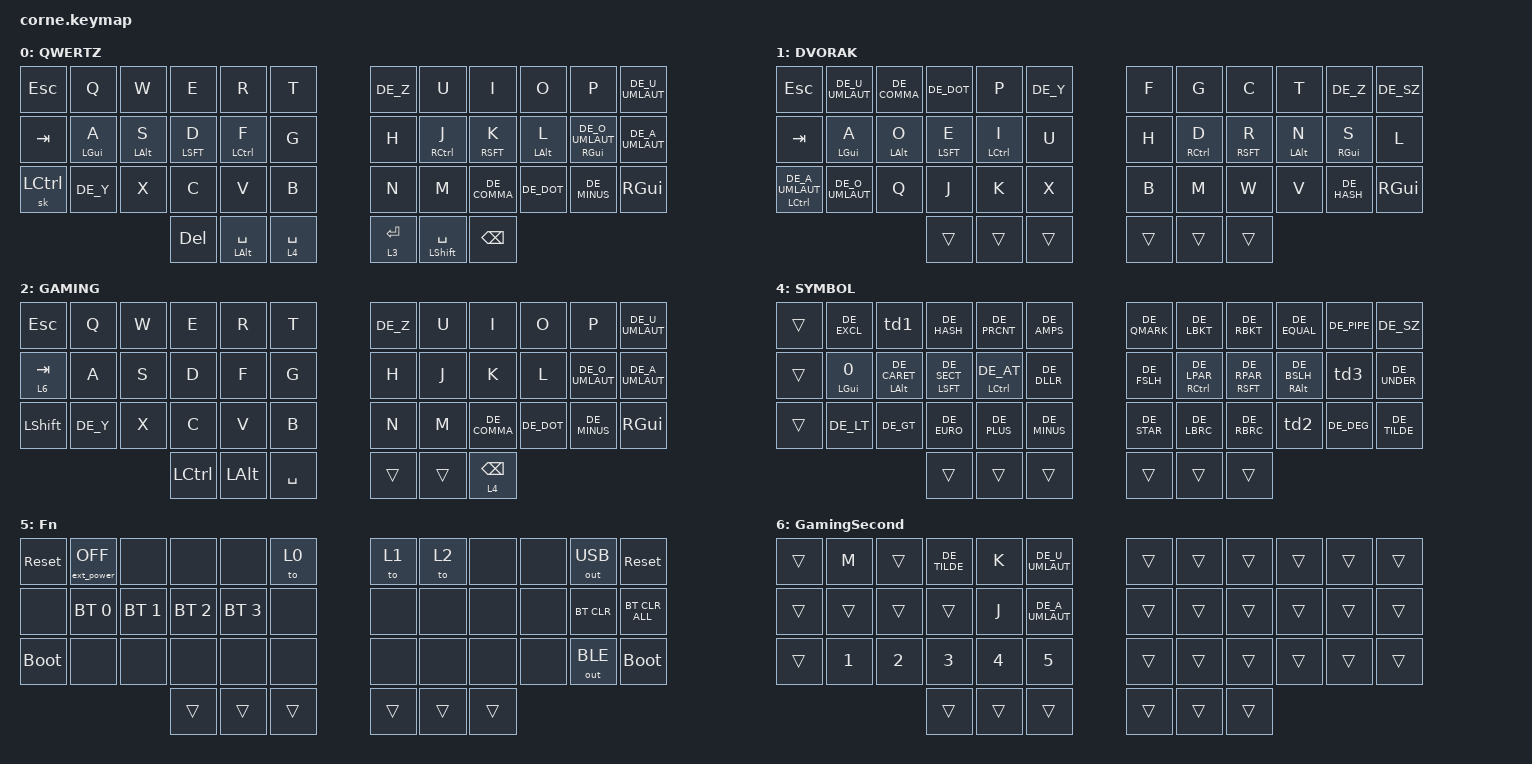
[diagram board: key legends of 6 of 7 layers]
/*
* Copyright (c) 2020 The ZMK Contributors
*
* SPDX-License-Identifier: MIT
*/

#include <behaviors.dtsi>
#include <dt-bindings/zmk/bt.h>
#include <dt-bindings/zmk/keys.h>
#include <dt-bindings/zmk/outputs.h>
#include <dt-bindings/zmk/rgb.h>
#include <dt-bindings/zmk/ext_power.h>
#include "keys_de.h"


/ {
  chosen {
    zmk,matrix_transform = &default_transform;

    // zmk,matrix_transform = &five_column_transform;
  };
};
  &soft_off { 
    hold-time-ms = <5000>; // Only turn off if the key is held for 5 seconds or longer. 
  };
  &lt {
    tapping-term-ms = <250>;
    flavor = "tap-preferred";
    quick-tap-ms = <0>;
  };
/ {
  conditional_layers {
    compatible = "zmk,conditional-layers";
    tri_layer {
      if-layers = <3 4>;
      then-layer = <5>;
    };
  };
  macros {
    FirstLet: FirstLet{
      compatible = "zmk,behavior-macro";
      #binding-cells = <0>;
      bindings
      = <&macro_tap &kp DE_CARET &kp SPACE>
      ;
    };
  };
  behaviors {
    td0: td0 {
      compatible = "zmk,behavior-tap-dance";
      label = "TD0";
      #binding-cells = <0>;
      bindings = <&kp LEFT_SHIFT>, <&kp CAPS>;
    };
    td1: td1 {
      compatible = "zmk,behavior-tap-dance";
      label = "TD1";
      #binding-cells = <0>;
      tapping-term-ms = <300>;
      bindings = <&kp DE_DQT>, <&kp DE_SQT>;
    };
    td2: td2 {
      compatible = "zmk,behavior-tap-dance";
      label = "TD2";
      #binding-cells = <0>;
      tapping-term-ms = <300>;
      bindings = <&kp DE_SQUARE>, <&kp DE_CUBE>, <&kp DE_MICRO>;
    };
    td3: td3 {
      compatible = "zmk,behavior-tap-dance";
      label = "TD3";
      #binding-cells = <0>;
      tapping-term-ms = <300>;
      bindings = <&hm RGUI DE_GRAVE>, <&kp DE_ACUTE>;
    };
    hm: homerow_mods {
      compatible = "zmk,behavior-hold-tap";
      #binding-cells = <2>;
      tapping-term-ms = <250>;    // <---[[moderate duration]]
      quick-tap-ms = <0>;
      flavor = "tap-preferred";
      bindings = <&kp>, <&kp>;
    };
    hmM: homerow_modsM {
      compatible = "zmk,behavior-hold-tap";
      #binding-cells = <2>;
      tapping-term-ms = <250>;    // <---[[moderate duration]]
      quick-tap-ms = <0>;
      flavor = "tap-preferred";
      bindings = <&kp>, <&FirstLet>;
    };
  };
  keymap {
    compatible = "zmk,keymap";

    default_layer {
      display-name = "QWERTZ";

                                  // --------------------------------------------------------------------------------
                                  // |  ESC |  Q  |  W  |  E  |  R  |  T  |***|  Z  |  U   |  I  |  O  |  P  |  Ü  |
                                  // |  TAB |  A  |  S  |  D  |  F  |  G  |***|  H  |  J   |  K  |  L  |  Ö  |  Ä  | 
                                  // | CRTL |  Y  |  X  |  C  |  V  |  B  |***|  N  |  M   |  ,  |  .  |  -  | WIN |
                                  //            | DEL | ALT SPACE | 4 SPC |***| 3 ENT | SHIFT SPACE | BSPC |

      bindings = <
        &kp ESC    &kp Q       &kp W       &kp E       &kp R       &kp T      &kp DE_Z  &kp U       &kp I         &kp O        &kp P                 &kp DE_U_UMLAUT
        &kp TAB    &hm LGUI A  &hm LALT S  &hm LSFT D  &hm LCTL F  &kp G      &kp H     &hm RCTL J  &hm RSFT K    &hm LALT L   &hm RGUI DE_O_UMLAUT  &kp DE_A_UMLAUT
        &sk LCTRL  &kp DE_Y    &kp X       &kp C       &kp V       &kp B      &kp N     &kp M       &kp DE_COMMA  &kp DE_DOT   &kp DE_MINUS          &kp RGUI
                                     &kp DEL  &hm LALT SPACE &lt 4 SPACE      &lt 3 ENTER  &hm LEFT_SHIFT SPACE &kp BSPC
      >;
    };
    layer_1 {
      display-name = "DVORAK";

                                                        // --------------------------------------------------------------------------------
                                                        // |  ESC |  Ü  |  ,  |  .  |  P  |  Y  |***|  F  |  G   |  C  |  T  |  Z  |  ß  |
                                                        // |  TAB |  A  |  O  |  E  |  I  |  U  |***|  H  |  D   |  R  |  N  |  S  |  L  | 
                                                        // |  Ä  |  Ö  |  Q  |  J  |  K  |  X   |***|  B  |  M   |  W  |  V  |  '  | WIN |
                                                        //       | DEL CTRL | ALT SPACE | 4 SPC |***| 3 ENT | SHIFT SPACE | BSPC |

      bindings = <
        &kp ESC               &kp DE_U_UMLAUT  &kp DE_COMMA  &kp DE_DOT   &kp P        &kp DE_Y      &kp F  &kp G        &kp C        &kp T        &kp DE_Z     &kp DE_SZ
        &kp TAB               &hm LGUI A       &hm LALT O    &hm LSFT E   &hm LCTL I   &kp U         &kp H  &hm RCTL D   &hm RSFT R   &hm LALT N   &hm RGUI S   &kp L
        &hm LCTL DE_A_UMLAUT  &kp DE_O_UMLAUT  &kp Q         &kp J        &kp K        &kp X         &kp B  &kp M        &kp W        &kp V        &kp DE_HASH  &kp RGUI
                                                                         &trans  &trans  &trans      &trans  &trans  &trans
      >;
    };
    layer_2 {
      display-name = "GAMING";

                      // --------------------------------------------------------------------------------
                      // |  ESC  |  Q  |  W  |  E  |  R  |  T  |***|  Z  |  U   |  I  |  O  |  P  |  Ü  |
                      // |  TAB  |  A  |  S  |  D  |  F  |  G  |***|  H  |  J   |  K  |  L  |  Ö  |  Ä  | 
                      // | SHIFT |  Y  |  X  |  C  |  V  |  B  |***|  N  |  M   |  ,  |  .  |  -  | WIN |
                      //                    | CRTL | ALT | SPC |***| 3 ENT | SHIFT SPACE | 4 BSPC |

      bindings = <
        &kp ESC         &kp Q     &kp W  &kp E  &kp R  &kp T       &kp DE_Z  &kp U  &kp I         &kp O       &kp P            &kp DE_U_UMLAUT
        &lt 6 TAB       &kp A     &kp S  &kp D  &kp F  &kp G       &kp H     &kp J  &kp K         &kp L       &kp DE_O_UMLAUT  &kp DE_A_UMLAUT
        &kp LEFT_SHIFT  &kp DE_Y  &kp X  &kp C  &kp V  &kp B       &kp N     &kp M  &kp DE_COMMA  &kp DE_DOT  &kp DE_MINUS     &kp RGUI
                              &kp LCTRL  &kp LALT  &kp SPACE       &trans  &trans  &lt 4 BSPC
      >;
    };
    layer_3 {
      display-name = "NUMBER";

                                                      // -----------------------------------------------------------------------------------------
                                                      // |  ESC |  1  |  2  |  3  |  4  |  5  |***|   6  |  7  |  8  |  9  |   0   |       |
                                                      // | TAB  |  0  |  ^  |     |  '  |  $  |***|  LFT | DWN |  UP | RGT | PG_DN | PG_UP |
                                                      // |  F1  | F2  | F3  | F4  | F5  | F6  |***|  F7  | F8  | F9  | F10 |  F11  |  F12  |
                                                      //            | DEL | ALT SPACE | 4 SPC |***| 3 ENT | SHIFT SPACE | BSPC |

      bindings = <
        &trans  &kp N1       &kp N2              &kp N3         &kp N4           &kp N5             &kp N6    &kp N7    &kp N8  &kp N9     &kp N0     &none
        &trans  &hm LGUI N0  &hmM LALT &FirstLet  &hm LSFT DE_AT &hm LCTL DE_SQT  &kp DE_DLLR       &kp LEFT  &kp DOWN  &kp UP  &kp RIGHT  &kp PG_DN  &kp PG_UP
        &kp F1  &kp F2       &kp F3              &kp F4         &kp F5           &kp F6             &kp F7    &kp F8    &kp F9  &kp F10    &kp F11    &kp F12
                                                                    &trans  &trans  &kp SPACE       &trans  &trans  &trans
      >;
    };

    layer_4 {
      display-name = "SYMBOL";

                                                        // -----------------------------------------------------------------------------------------
                                                        // |  ESC |  !  |  "' |  #  |  % |  &  |***|  ?  |  [  |  ]  |  =  | "|" |  ß |
                                                        // | TAB |    |  ^  |  §  |  @  |  $  |***|  /  |  (  |  )  |  \  | `´  |  _  |
                                                        // | CRTL |  <  | >  |  €  |  +  |  -  |***|  *  |  {  |  }  | ²³µ |  °  | ~  |
                                                        //           | DEL | ALT SPACE | 4 SPC |***| 3 ENT | SHIFT SPACE | BSPC |

      bindings = <
        &trans  &kp DE_EXCL  &td1               &kp DE_HASH       &kp DE_PRCNT    &kp DE_AMPS        &kp DE_QMARK  &kp DE_LBKT       &kp DE_RBKT       &kp DE_EQUAL      &kp DE_PIPE  &kp DE_SZ
        &trans  &hm LGUI N0  &hm LALT DE_CARET  &hm LSFT DE_SECT  &hm LCTL DE_AT  &kp DE_DLLR        &kp DE_FSLH   &hm RCTL DE_LPAR  &hm RSFT DE_RPAR  &hm RALT DE_BSLH  &td3         &kp DE_UNDER
        &trans  &kp DE_LT    &kp DE_GT          &kp DE_EURO       &kp DE_PLUS     &kp DE_MINUS       &kp DE_STAR   &kp DE_LBRC       &kp DE_RBRC       &td2              &kp DE_DEG   &kp DE_TILDE
                                                                        &trans  &trans  &trans       &trans  &trans  &trans
      >;
    };

    layer_5 {
      display-name = "Fn";

                                                // -----------------------------------------------------------------------------------------
                                                // | reset |     |     |     |    |Lay0|***|Lay1     |  Lay2   |    |    |            | reset      |
                                                // | BT0   | BT1 | BT2 | BT3 |    |    |***|         |         |    |    | BT CLR CUR | BT CLR ALL |
                                                // | boot  |     |     |     |    |    |***|         |         |    |    |            | boot       |
                                                //           | DEL | ALT SPACE | 4 SPC |***| 3 ENT | SHIFT SPACE | BSPC |

      bindings = <
        &sys_reset   &ext_power EP_OFF  &none         &none         &none         &to 0       &to 1  &to 2  &none  &none  &out OUT_USB  &sys_reset
        &none        &bt BT_SEL 0       &bt BT_SEL 1  &bt BT_SEL 2  &bt BT_SEL 3  &none       &none  &none  &none  &none  &bt BT_CLR    &bt BT_CLR_ALL
        &bootloader  &none              &none         &none         &none         &none       &none  &none  &none  &none  &out OUT_BLE  &bootloader
                                                                &trans  &trans  &trans       &trans  &trans  &trans
      >;
    };

    layer_6 {
      display-name = "GamingSecond";

                    // --------------------------------------------------------------------------------
                    // |  ESC  |  M  |  W  |  E  |  R  |  T  |***|  Z  |  U   |  I  |  O  |  P  |  Ü  |
                    // |  TAB  |  A  |  S  |  D  |  F  |  G  |***|  H  |  J   |  K  |  L  |  Ö  |  Ä  |
                    // | SHIFT |  1  |  2  |  3  |  4  |  5  |***|  N  |  M   |  ,  |  .  |  -  | WIN |
                    //                    | CRTL | ALT | SPC |***| 3 ENT | SHIFT SPACE | 4 BSPC |

      bindings = <
        &trans  &kp M   &trans  &kp DE_TILDE  &kp K   &kp DE_U_UMLAUT       &trans  &trans  &trans  &trans  &trans  &trans
        &trans  &trans  &trans  &trans        &kp J   &kp DE_A_UMLAUT       &trans  &trans  &trans  &trans  &trans  &trans
        &trans  &kp N1  &kp N2  &kp N3        &kp N4  &kp N5               &trans  &trans  &trans  &trans  &trans  &trans
                                              &trans  &trans  &trans       &trans  &trans  &trans
      >;
    };
  };
};

